AUTOSAR XML (schema 4-3-0)
package /ComponentTypes
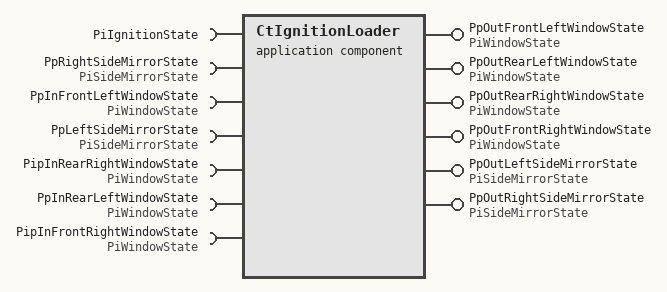
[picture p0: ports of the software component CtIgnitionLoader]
  application sw component type CtIgnitionLoader
    7 x require port:
      PiIgnitionState: nonqueued-receiver-com-spec{data-element=DeIgnitionState, init-value=0}, required-interface=PiIgnitionState
      PpRightSideMirrorState: nonqueued-receiver-com-spec{data-element=DeSidMirrorState, init-value=0}, required-interface=PiSideMirrorState
      PpInFrontLeftWindowState: nonqueued-receiver-com-spec=data-element=DeWindowState, required-interface=PiWindowState
      PpLeftSideMirrorState: nonqueued-receiver-com-spec{data-element=DeSidMirrorState, init-value=0}, required-interface=PiSideMirrorState
      PipInRearRightWindowState: nonqueued-receiver-com-spec{data-element=DeWindowState, init-value=0}, required-interface=PiWindowState
      PpInRearLeftWindowState: nonqueued-receiver-com-spec{data-element=DeWindowState, init-value=0}, required-interface=PiWindowState
      PipInFrontRightWindowState: nonqueued-receiver-com-spec=data-element=DeWindowState, required-interface=PiWindowState
    6 x provide port:
      PpOutFrontLeftWindowState: nonqueued-sender-com-spec{data-element=DeWindowState, init-value=0}, provided-interface=PiWindowState
      PpOutRearLeftWindowState: nonqueued-sender-com-spec{data-element=DeWindowState, init-value=0}, provided-interface=PiWindowState
      PpOutRearRightWindowState: nonqueued-sender-com-spec{data-element=DeWindowState, init-value=0}, provided-interface=PiWindowState
      PpOutFrontRightWindowState: nonqueued-sender-com-spec{data-element=DeWindowState, init-value=0}, provided-interface=PiWindowState
      PpOutLeftSideMirrorState: nonqueued-sender-com-spec{data-element=DeSidMirrorState, init-value=0}, provided-interface=PiSideMirrorState
      PpOutRightSideMirrorState: nonqueued-sender-com-spec{data-element=DeSidMirrorState, init-value=0}, provided-interface=PiSideMirrorState
    behavior CtIgnitionLoader_InternalBehavior
  swc implementation CtIgnitionLoader_Implementation: behavior=CtIgnitionLoader_InternalBehavior
